AUTOSAR XML (schema 4-2-2)
standard types defined: uint16, uint64, uint8_least, uint16_least, uint32_least, sint8_least, sint16_least, sint32_least, Boolean, SInt32, SInt16, SInt8, UInt32, UInt8, UInt64
package /NvM_SWC
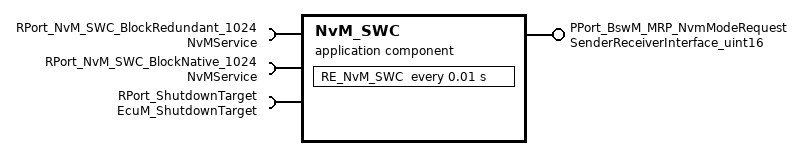
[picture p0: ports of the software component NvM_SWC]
  application sw component type NvM_SWC
    require port RPort_NvM_SWC_BlockRedundant_1024: required-interface=NvMService
    require port RPort_NvM_SWC_BlockNative_1024: required-interface=NvMService
    require port RPort_ShutdownTarget: required-interface=EcuM_ShutdownTarget
    provide port PPort_BswM_MRP_NvmModeRequest: provided-interface=SenderReceiverInterface_uint16
    behavior IB_NvM_SWC: data-type-mapping=DTMS
      timing event TE_NvM_SWC_10ms: start-on-event=RE_NvM_SWC, period=0.01
      per instance memory NvM_SWC_BlockNative_1024: implementation-data-type=Impl_NvM_DstPtrType_1024, type=NvM_SWC_BlockNative_1024_Type, type-definition=Impl_NvM_DstPtrType_1024
      per instance memory NvM_SWC_BlockRedundant_1024: implementation-data-type=Impl_NvM_DstPtrType_1024, type=NvM_SWC_BlockRedundant_1024_Type, type-definition=Impl_NvM_DstPtrType_1024
      runnable RE_NvM_SWC: can-be-invoked-concurrently=true, symbol=RE_NvM_SWC_func
        data-send-points:
          access DSP_VDP_uint16_0: accessed-variable=PPort_BswM_MRP_NvmModeRequest.VDP_uint16
        23 x sync call:
          SSCP_RPort_NvM_SWC_BlockNative_1024_EraseBlock: operation=RPort_NvM_SWC_BlockNative_1024.EraseBlock
          SSCP_RPort_NvM_SWC_BlockNative_1024_GetDataIndex: operation=RPort_NvM_SWC_BlockNative_1024.GetDataIndex
          SSCP_RPort_NvM_SWC_BlockNative_1024_SetRamBlockStatus: operation=RPort_NvM_SWC_BlockNative_1024.SetRamBlockStatus
          SSCP_RPort_NvM_SWC_BlockNative_1024_WriteBlock: operation=RPort_NvM_SWC_BlockNative_1024.WriteBlock
          SSCP_RPort_NvM_SWC_BlockRedundant_1024_EraseBlock: operation=RPort_NvM_SWC_BlockRedundant_1024.EraseBlock
          SSCP_RPort_NvM_SWC_BlockRedundant_1024_GetDataIndex: operation=RPort_NvM_SWC_BlockRedundant_1024.GetDataIndex
          SSCP_RPort_NvM_SWC_BlockRedundant_1024_GetErrorStatus: operation=RPort_NvM_SWC_BlockRedundant_1024.GetErrorStatus
          SSCP_RPort_NvM_SWC_BlockRedundant_1024_InvalidateNvBlock: operation=RPort_NvM_SWC_BlockRedundant_1024.InvalidateNvBlock
          SSCP_RPort_NvM_SWC_BlockRedundant_1024_ReadBlock: operation=RPort_NvM_SWC_BlockRedundant_1024.ReadBlock
          SSCP_RPort_NvM_SWC_BlockRedundant_1024_RestoreBlockDefaults: operation=RPort_NvM_SWC_BlockRedundant_1024.RestoreBlockDefaults
          SSCP_RPort_NvM_SWC_BlockRedundant_1024_SetDataIndex: operation=RPort_NvM_SWC_BlockRedundant_1024.SetDataIndex
          SSCP_RPort_NvM_SWC_BlockRedundant_1024_SetRamBlockStatus: operation=RPort_NvM_SWC_BlockRedundant_1024.SetRamBlockStatus
          SSCP_RPort_NvM_SWC_BlockRedundant_1024_WriteBlock: operation=RPort_NvM_SWC_BlockRedundant_1024.WriteBlock
          SSCP_RPort_NvM_SWC_BlockNative_1024_GetErrorStatus: operation=RPort_NvM_SWC_BlockNative_1024.GetErrorStatus
          SSCP_RPort_NvM_SWC_BlockNative_1024_InvalidateNvBlock: operation=RPort_NvM_SWC_BlockNative_1024.InvalidateNvBlock
          SSCP_RPort_NvM_SWC_BlockNative_1024_ReadBlock: operation=RPort_NvM_SWC_BlockNative_1024.ReadBlock
          SSCP_RPort_NvM_SWC_BlockNative_1024_RestoreBlockDefaults: operation=RPort_NvM_SWC_BlockNative_1024.RestoreBlockDefaults
          SSCP_RPort_NvM_SWC_BlockNative_1024_SetDataIndex: operation=RPort_NvM_SWC_BlockNative_1024.SetDataIndex
          SSCP_RPort_ShutdownTarget_SelectShutdownTarget: operation=RPort_ShutdownTarget.SelectShutdownTarget
          SSCP_RPort_ShutdownTarget_GetShutdownTarget: operation=RPort_ShutdownTarget.GetShutdownTarget
          SSCP_RPort_ShutdownTarget_GetLastShutdownTarget: operation=RPort_ShutdownTarget.GetLastShutdownTarget
          SSCP_RPort_ShutdownTarget_SelectShutdownCause: operation=RPort_ShutdownTarget.SelectShutdownCause
          SSCP_RPort_ShutdownTarget_GetShutdownCause: operation=RPort_ShutdownTarget.GetShutdownCause
      swc service dependency SwcSD_NvM_SWC_Block1
        assigned-datas:
          role=ramBlock, used-pim=NvM_SWC_BlockNative_1024
          role=ramBlock, used-pim=NvM_SWC_BlockRedundant_1024
        service-needs:
          nv block needs NvBlockNeeds_NvM: category=READ, calc-ram-block-crc=false, check-static-block-id=false, n-rom-blocks=0, readonly=false, restore-at-start=true, store-at-shutdown=true, write-only-once=false
package /IMPL_NvM_SWC
  swc implementation IMPL_NvM_SWC: programming-language=C, behavior=IB_NvM_SWC
    code-descriptors:
      code IMPL_NvM_SWC_Code: artifact-descriptors=autosar-engineering-object={short-label=CodeDescriptor_NvM_SWC, category=SWSRC}
package /NvM/SwBaseTypes
  base type uint4: category=FIXED_LENGTH, base-type-size=8, base-type-encoding=NONE, mem-alignment=1, native-declaration=uint8
package /NvM/ImplementationDataTypes
  4 x impl type:
    Impl_NvM_BlockIdType: category=VALUE, base-type=uint16, range phys 0..65535, raw 0..65535
    Impl_NvM_RequestResultType: category=VALUE, base-type=uint4, range phys 0..6, raw 0..6
    Impl_NvM_DstPtrType: category=ARRAY
      element ArrayElement: array-size=512, array-size-semantics=FIXED-SIZE, implementation-data-type=uint8
    Impl_NvM_DstPtrType_1024: category=ARRAY
      element ArrayElement: array-size=1024, array-size-semantics=FIXED-SIZE, implementation-data-type=uint8
package /NvM/DataTypeMappingSets
  data type mapping set DTMS
    data-type-maps:
      Uint8
      application-data-type=NvM_DstPtrType, implementation-data-type=Impl_NvM_DstPtrType
      application-data-type=NvM_DstPtrType, implementation-data-type=Impl_NvM_DstPtrType_1024
package /NvM/DataConstrs
  range UInt4: phys 0..15, raw 0..15
package /DataTypes
  app type AuxU8_NvM_DstPtrType: category=VALUE
  app type NvM_BlockIdType: category=VALUE, compu {identical}
  app type Uint8: category=VALUE, compu {identical}, range phys 0..255, raw 0..255, invalid-value=0
  application array data type NvM_DstPtrType: category=ARRAY
    element ArrayElement: category=VALUE, type=AuxU8_NvM_DstPtrType, max-number-of-elements=5
  range AuxU8_NvM_DstPtrType_DC: phys 0..255, raw 0..255
  range NvM_DstPtrType_DC: phys 0..255, raw 0..255
